AUTOSAR XML (schema 4-0-3)
package /ComponentTypes
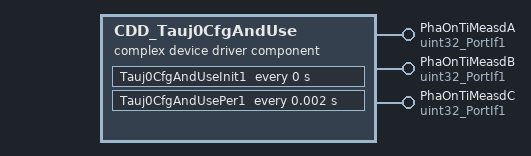
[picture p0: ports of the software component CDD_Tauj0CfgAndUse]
  complex device driver sw component type CDD_Tauj0CfgAndUse
    provide port PhaOnTiMeasdA: nonqueued-sender-com-spec{data-element=Val, init-value=0}, provided-interface=uint32_PortIf1
    provide port PhaOnTiMeasdB: nonqueued-sender-com-spec{data-element=Val, init-value=0}, provided-interface=uint32_PortIf1
    provide port PhaOnTiMeasdC: nonqueued-sender-com-spec{data-element=Val, init-value=0}, provided-interface=uint32_PortIf1
    behavior CDD_Tauj0CfgAndUse_InternalBehavior
      ar-typed-per-instance-memorys:
        data PhaOnTiCntrAPrev: sw-calibration-access=READ-ONLY, type=uint32
        data PhaOnTiCntrBPrev: sw-calibration-access=READ-ONLY, type=uint32
        data PhaOnTiCntrCPrev: sw-calibration-access=READ-ONLY, type=uint32
      timing event Tauj0CfgAndUse_InitEvent: start-on-event=Tauj0CfgAndUseInit1, period=0
      timing event TMT_Tauj0CfgAndUsePer1: start-on-event=Tauj0CfgAndUsePer1, period=0.002
      runnable Tauj0CfgAndUseInit1
      runnable Tauj0CfgAndUsePer1
        data-send-points:
          access SEND_PhaOnTiMeasdA_Val: accessed-variable=PhaOnTiMeasdA.Val
          access SEND_PhaOnTiMeasdB_Val: accessed-variable=PhaOnTiMeasdB.Val
          access SEND_PhaOnTiMeasdC_Val: accessed-variable=PhaOnTiMeasdC.Val
  swc implementation CDD_Tauj0CfgAndUse_Implementation: behavior=CDD_Tauj0CfgAndUse_InternalBehavior
    code-descriptors:
      code Default: artifact-descriptors=autosar-engineering-object={short-label=Default, category=SWSRC}
